# GD32E53x register map
File version: 1.0
CPU: CM33 r0p4, little endian, MPU, FPU, 4 interrupt priority bits
Registers are 32-bit, read-write, reset 0x0 unless marked. A register's access mark holds for its fields unless they carry their own. Offsets are from the block's base; [hi:lo] are bit positions; {n}, {i} and the like mark numbered series; 'fields as' and 'values as' point back to an identical list.

## TIMER5 — Basic-timers
Base 0x40001000
Same registers: TIMER6 0x40001400, TIMER50 0x4000EC00, TIMER51 0x4000F000
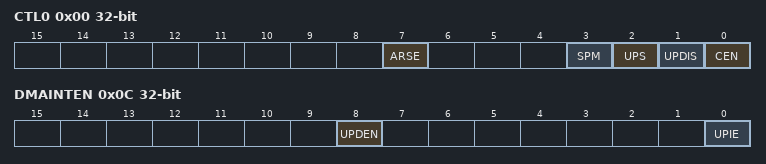
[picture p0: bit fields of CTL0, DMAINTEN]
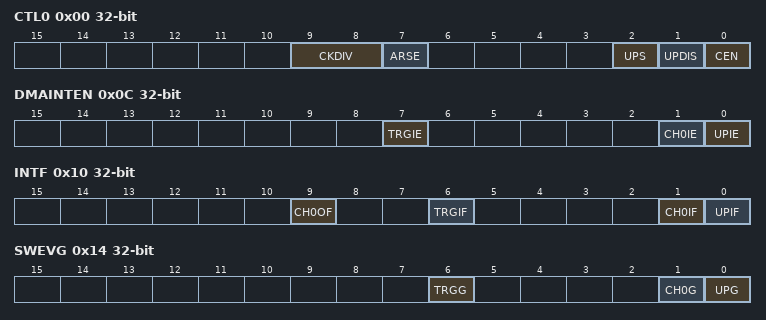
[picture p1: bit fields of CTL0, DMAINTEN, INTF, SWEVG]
0x00 CTL0 — control register 0
  [7] ARSE — Auto-reload shadow enable
  [3] SPM — Single pulse mode
  [2] UPS — Update source
  [1] UPDIS — Update disable
  [0] CEN — Counter enable
0x04 CTL1 — control register 1
  [6:4] MMC — Master mode control
0x0C DMAINTEN — DMA/Interrupt enable register
  [8] UPDEN — Update DMA request enable
  [0] UPIE — Update interrupt enable
0x10 INTF — Interrupt flag register
  [0] UPIF — Update interrupt flag
0x14 SWEVG wo — event generation register
  [0] UPG — Update generation
0x24 CNT — Counter register
  [15:0] CNT — Low counter value
0x28 PSC — Prescaler register
  [15:0] PSC — Prescaler value of the counter clock
0x2C CAR — Counter auto reload register
  [15:0] CARL — Counter auto reload value

## TIMER9 — General-purpose-timers
Base 0x40015000
Same registers: TIMER12 0x40001C00, TIMER13 0x40002000, TIMER10 0x40015400
0x00 CTL0 — control register 0
  [9:8] CKDIV — Clock division
  [7] ARSE — Auto-reload shadow enable
  [2] UPS — Update source
  [1] UPDIS — Update disable
  [0] CEN — Counter enable
0x04 CTL1 — control register 1
  [6:4] MMC — Master mode control
0x08 SMCFG — Slave mode configuration register
  [7] MSM — Master-slave mode
0x0C DMAINTEN — DMA/Interrupt enable register
  [7] TRGIE — Trigger interrupt enable
  [1] CH0IE — Channel 0 capture/compare interrupt enable
  [0] UPIE — Update interrupt enable
0x10 INTF — interrupt flag register
  [9] CH0OF — Channel 0 over capture flag
  [6] TRGIF — Trigger interrupt flag
  [1] CH0IF — Channel 0 capture/compare interrupt flag
  [0] UPIF — Update interrupt flag
0x14 SWEVG wo — event generation register
  [6] TRGG — Trigger event generation
  [1] CH0G — Channel 0 capture or compare event generation
  [0] UPG — Update generation
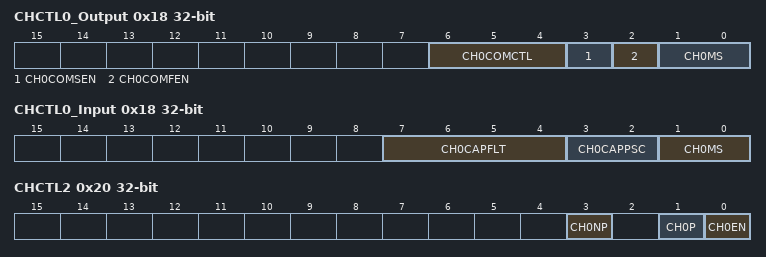
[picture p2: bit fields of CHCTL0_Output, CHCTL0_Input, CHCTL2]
0x18 CHCTL0_Output — Channel control register 0 (output mode)
  [6:4] CH0COMCTL — Channel 0 compare output control
  [3] CH0COMSEN — Channel 0 compare output shadow enable
  [2] CH0COMFEN — Channel 0 output compare fast enable
  [1:0] CH0MS — Channel 0 I/O mode selection
0x18 CHCTL0_Input (alternate view of CHCTL0_Output) — Channel control register 0 ( (input mode)
  [7:4] CH0CAPFLT — Channel 0 input capture filter control
  [3:2] CH0CAPPSC — Channel 0 input capture prescaler
  [1:0] CH0MS — Channel 0 mode selection
0x20 CHCTL2 — Channel control register 2
  [3] CH0NP — Channel 0 complementary output polarity
  [1] CH0P — Channel 0 capture/compare polarity
  [0] CH0EN — Channel 0 capture/compare function enable
0x24 CNT — Counter register
  [15:0] CNT — current counter value
0x28 PSC — Prescaler register
  [15:0] PSC — Prescaler value of the counter clock
0x2C CAR — Counter auto reload register
  [15:0] CARL — Counter auto reload value
0x34 CH0CV — Channel 0 capture/compare value register
  [15:0] CH0VAL — Capture or compare value of channel 0
0xFC CFG — configuration register
  [1] CHVSEL — Write CHxVAL register selection

## TRNG — True random number generator
Base 0x40023C00
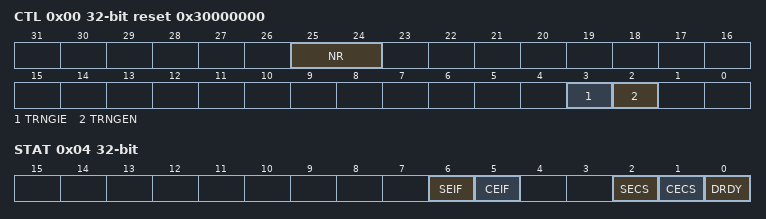
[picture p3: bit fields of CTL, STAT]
0x00 CTL reset 0x30000000 — Control register
  [25:24] NR — analog rng power mode.
  [3] TRNGIE — Interrupt enabled bit.
  [2] TRNGEN — TRNG enabled bit.
0x04 STAT access per field — Status register
  [6] SEIF rw — Seed error interrupt flag
  [5] CEIF rw — Clock error interrupt flag
  [2] SECS ro — Seed error current status
  [1] CECS ro — Clock error current status
  [0] DRDY ro — Random data ready status bit. This bit is cleared by reading the TRNG_DATA register and set when a new random number is generated.
0x08 DATA ro
  [31:0] TRNGDATA — 32-bit random data

## USBFS_HOST — USB on the go full speed host
Base 0x50000400
0x00 HCTL — host configuration register (HCTL)
  [1:0] CLKSEL — clock select for USB clock
0x04 HFT reset 0xBB80 — Host frame interval register
  [15:0] FRI — Frame interval
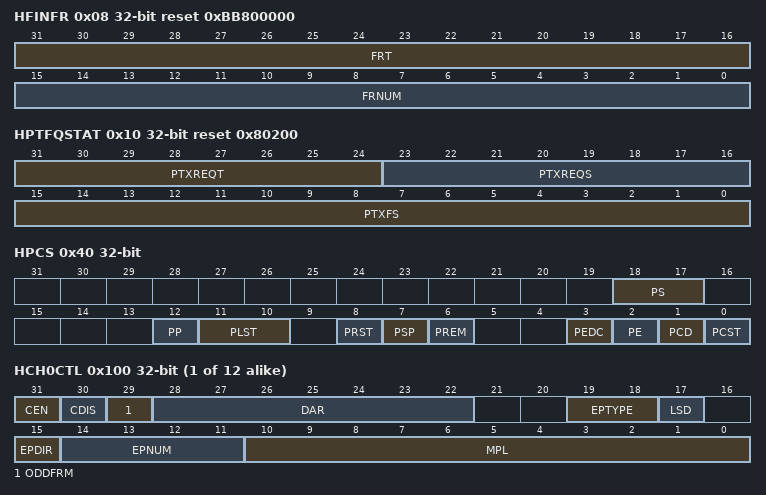
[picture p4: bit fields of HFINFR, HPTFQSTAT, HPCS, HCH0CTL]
0x08 HFINFR ro reset 0xBB800000 — OTG_FS host frame number/frame time remaining register (HFINFR)
  [31:16] FRT — Frame remaining time
  [15:0] FRNUM — Frame number
0x10 HPTFQSTAT ro reset 0x80200 — Host periodic transmit FIFO/queue status register (HPTFQSTAT)
  [31:24] PTXREQT — Top of the periodic transmit request queue
  [23:16] PTXREQS — Periodic transmit request queue space available
  [15:0] PTXFS — Periodic transmit data FIFO space available
0x14 HACHINT ro — Host all channels interrupt register
  [11:0] HACHINT — Host all channel interrupts
0x18 HACHINTEN — host all channels interrupt mask register
  [11:0] CINTEN — Channel interrupt enable
0x40 HPCS access per field — Host port control and status register (USBFS_HPCS)
  [18:17] PS ro — Port speed
  [12] PP rw — Port power
  [11:10] PLST ro — Port line status
  [8] PRST rw — Port reset
  [7] PSP rw — Port suspend
  [6] PREM rw — Port resume
  [3] PEDC rw — Port enable/disable change
  [2] PE rw — Port enable
  [1] PCD rw — Port connect detected
  [0] PCST ro — Port connect status
{0x100+0x20*i} HCH{i}CTL (i=0..11) — host channel-{i} characteristics register (HCH{i}CTL)
  [31] CEN — Channel enable
  [30] CDIS — Channel disable
  [29] ODDFRM — Odd frame
  [28:22] DAR — Device address
  [19:18] EPTYPE — Endpoint type
  [17] LSD — Low-speed device
  [15] EPDIR — Endpoint direction
  [14:11] EPNUM — Endpoint number
  [10:0] MPL — Maximum packet size
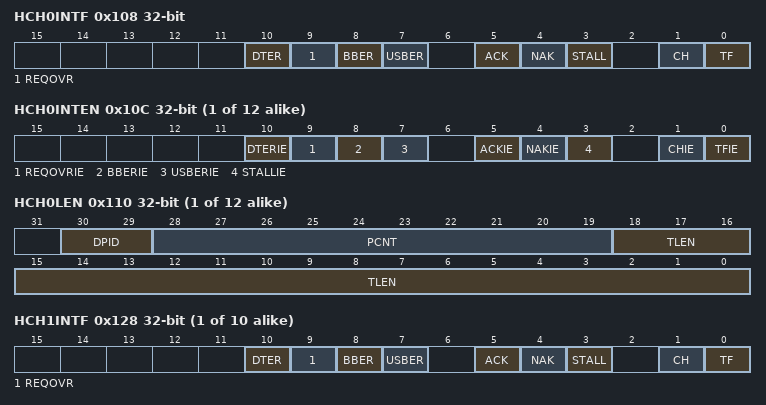
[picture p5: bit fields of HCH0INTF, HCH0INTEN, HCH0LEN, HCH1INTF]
0x108 HCH0INTF — host channel-0 interrupt register (USBFS_HCHxINTF)
  [10] DTER — Data toggle error
  [9] REQOVR — Request queue overrun
  [8] BBER — Babble error
  [7] USBER — USB bus error
  [5] ACK — ACK response received/transmitted interrupt
  [4] NAK — NAK response received interrupt
  [3] STALL — STALL response received interrupt
  [1] CH — Channel halted
  [0] TF — Transfer finished
{0x10C+0x20*i} HCH{i}INTEN (i=0..11) — host channel-{i} interrupt enable register (HCH{i}INTEN)
  [10] DTERIE — Data toggle error interrupt enable
  [9] REQOVRIE — request queue overrun interrupt enable
  [8] BBERIE — Babble error interrupt enable
  [7] USBERIE — USB bus error interrupt enable
  [5] ACKIE — ACK interrupt enable
  [4] NAKIE — NAK interrupt enable
  [3] STALLIE — STALL interrupt enable
  [1] CHIE — Channel halted interrupt enable
  [0] TFIE — Transfer completed interrupt enable
{0x110+0x20*i} HCH{i}LEN (i=0..11) — host channel-{i} transfer length register
  [30:29] DPID — Data PID
  [28:19] PCNT — Packet count
  [18:0] TLEN — Transfer length
{0x108+0x20*i} HCH{i}INTF (i=1..10) — host channel-{i} interrupt register (HCH{i}INTF)
  fields as HCH0INTF
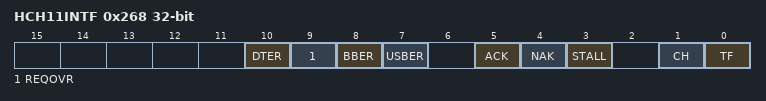
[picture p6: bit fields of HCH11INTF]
0x268 HCH11INTF — host channel-11 interrupt register (HCH10INTF)
  fields as HCH0INTF

## USBFS_PWRCLK — USB on the go full speed
Base 0x50000E00
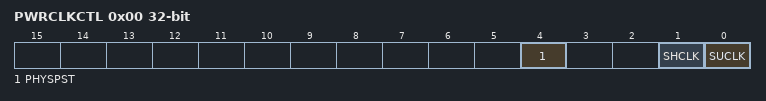
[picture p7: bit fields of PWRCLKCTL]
0x00 PWRCLKCTL — power and clock gating control register (PWRCLKCTL)
  [4] PHYSPST — Suspended status
  [1] SHCLK — Stop HCLK
  [0] SUCLK — Stop the USB clock

## WWDGT — Window watchdog timer
Base 0x40002C00
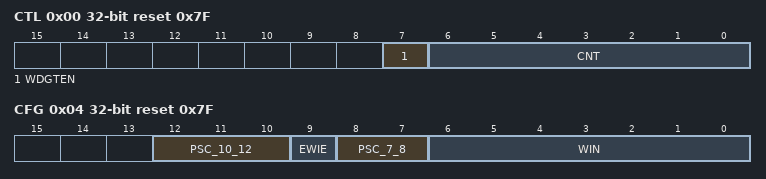
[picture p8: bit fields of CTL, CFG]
0x00 CTL reset 0x7F — Control register
  [7] WDGTEN — Activation bit
  [6:0] CNT — 7-bit counter
0x04 CFG reset 0x7F — Configuration register
  [12:10] PSC_10_12 — High bit value of prescaler
  [9] EWIE — Early wakeup interrupt
  [8:7] PSC_7_8 — Prescaler
  [6:0] WIN — 7-bit window value
0x08 STAT — Status register
  [0] EWIF — Early wakeup interrupt flag
